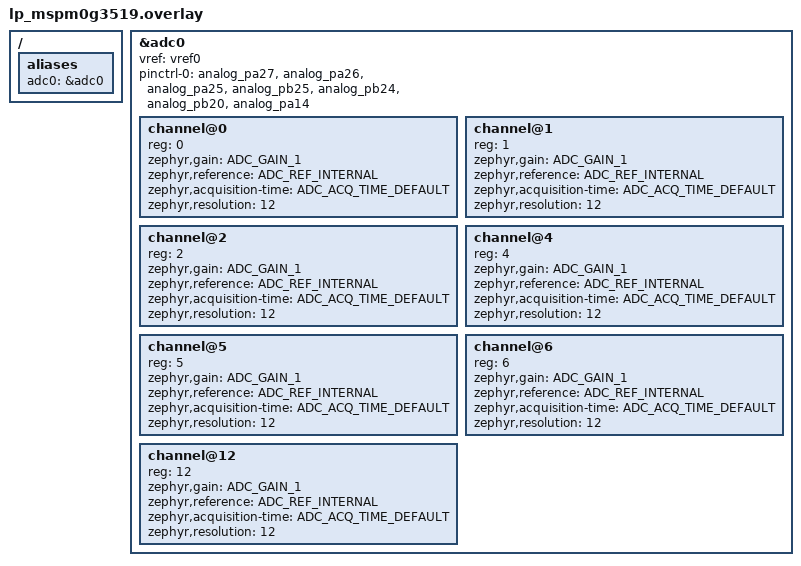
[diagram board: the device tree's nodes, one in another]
/*
 * SPDX-FileCopyrightText: 2026 Texas Instruments Incorporated
 *
 * SPDX-License-Identifier: Apache-2.0
 */

#include <dt-bindings/adc/adc.h>

/ {
	aliases {
		adc0 = &adc0;
	};
};


&adc0 {
	vref = <&vref0>;
	pinctrl-0 = <
		&analog_pa27 /* ADC0.0 */
		&analog_pa26 /* ADC0.1 */
		&analog_pa25 /* ADC0.2 */
		&analog_pb25 /* ADC0.4 */
		&analog_pb24 /* ADC0.5 */
		&analog_pb20 /* ADC0.6 */
		&analog_pa14 /* ADC0.12 */
	>;
	pinctrl-names = "default";
	status = "okay";
	#address-cells = <1>;
	#size-cells = <0>;
	channel@0 {
		reg = <0>;
		zephyr,gain = "ADC_GAIN_1";
		zephyr,reference = "ADC_REF_INTERNAL";
		zephyr,acquisition-time = <ADC_ACQ_TIME_DEFAULT>;
		zephyr,resolution = <12>;
	};

	channel@1 {
		reg = <1>;
		zephyr,gain = "ADC_GAIN_1";
		zephyr,reference = "ADC_REF_INTERNAL";
		zephyr,acquisition-time = <ADC_ACQ_TIME_DEFAULT>;
		zephyr,resolution = <12>;
	};

	channel@2 {
		reg = <2>;
		zephyr,gain = "ADC_GAIN_1";
		zephyr,reference = "ADC_REF_INTERNAL";
		zephyr,acquisition-time = <ADC_ACQ_TIME_DEFAULT>;
		zephyr,resolution = <12>;
	};

	channel@4 {
		reg = <4>;
		zephyr,gain = "ADC_GAIN_1";
		zephyr,reference = "ADC_REF_INTERNAL";
		zephyr,acquisition-time = <ADC_ACQ_TIME_DEFAULT>;
		zephyr,resolution = <12>;
	};

	channel@5 {
		reg = <5>;
		zephyr,gain = "ADC_GAIN_1";
		zephyr,reference = "ADC_REF_INTERNAL";
		zephyr,acquisition-time = <ADC_ACQ_TIME_DEFAULT>;
		zephyr,resolution = <12>;
	};

	channel@6 {
		reg = <6>;
		zephyr,gain = "ADC_GAIN_1";
		zephyr,reference = "ADC_REF_INTERNAL";
		zephyr,acquisition-time = <ADC_ACQ_TIME_DEFAULT>;
		zephyr,resolution = <12>;
	};

	channel@12 {
		reg = <12>;
		zephyr,gain = "ADC_GAIN_1";
		zephyr,reference = "ADC_REF_INTERNAL";
		zephyr,acquisition-time = <ADC_ACQ_TIME_DEFAULT>;
		zephyr,resolution = <12>;
	};
};
